# M3H5 register map
File version: 0.1
Registers are 32-bit, read-write, reset 0x0 unless marked. A register's access mark holds for its fields unless they carry their own. Offsets are from the block's base; [hi:lo] are bit positions; {n}, {i} and the like mark numbered series.

## PL
Base 0x400C0A00
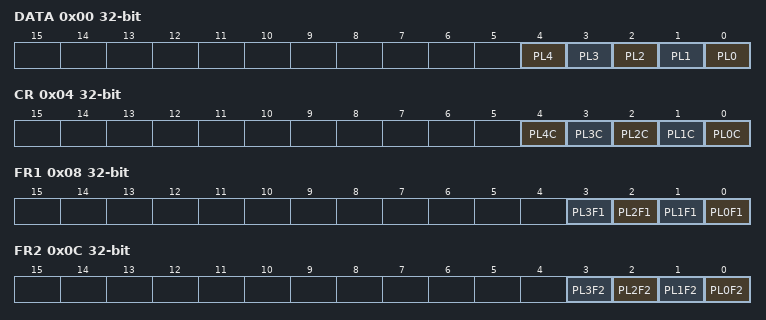
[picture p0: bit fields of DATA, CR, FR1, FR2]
0x00 DATA — PL Data Register
  [n] PL{n} (n=0..4)
0x04 CR — PL Control Register
  [n] PL{n}C (n=0..4)
0x08 FR1 — PL Function Register 1
  [n] PL{n}F1 (n=0..3)
0x0C FR2 — PL Function Register 2
  [n] PL{n}F2 (n=0..3)
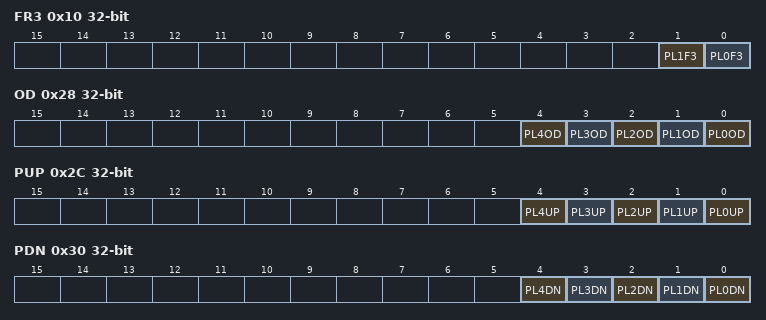
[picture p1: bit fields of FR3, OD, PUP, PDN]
0x10 FR3 — PL Function Register 3
  [1] PL1F3, [0] PL0F3
0x28 OD — PL Open Drain Control Register
  [n] PL{n}OD (n=0..4)
0x2C PUP — PL Pull-up Control Register
  [n] PL{n}UP (n=0..4)
0x30 PDN — PL Pull-Down Control Register
  [n] PL{n}DN (n=0..4)
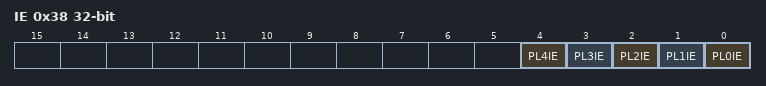
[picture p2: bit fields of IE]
0x38 IE — PL Input Enable Control Register
  [n] PL{n}IE (n=0..4)

## PM
Base 0x400C0B00
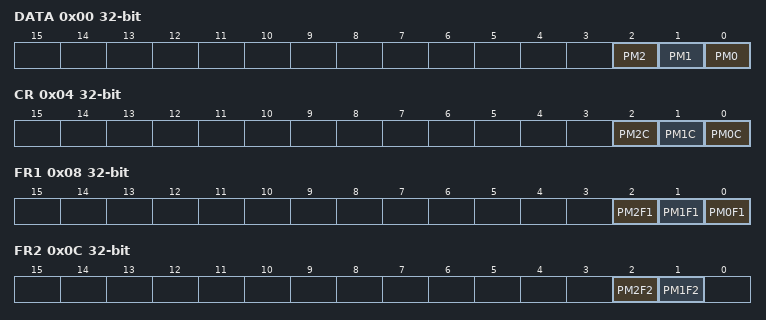
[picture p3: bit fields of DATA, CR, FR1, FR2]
0x00 DATA — PM Data Register
  [2] PM2, [1] PM1, [0] PM0
0x04 CR — PM Control Register
  [2] PM2C, [1] PM1C, [0] PM0C
0x08 FR1 — PM Function Register 1
  [2] PM2F1, [1] PM1F1, [0] PM0F1
0x0C FR2 — PM Function Register 2
  [2] PM2F2, [1] PM1F2
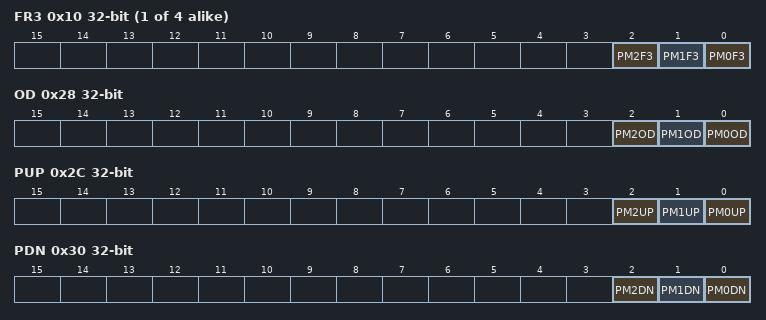
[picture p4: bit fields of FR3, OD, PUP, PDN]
{0x4+4i} FR{i} (i=3..6) — PM Function Register {i}
  [2] PM2F{i}, [1] PM1F{i}, [0] PM0F{i}
0x28 OD — PM Open Drain Control Register
  [2] PM2OD, [1] PM1OD, [0] PM0OD
0x2C PUP — PM Pull-up Control Register
  [2] PM2UP, [1] PM1UP, [0] PM0UP
0x30 PDN — PM Pull-Down Control Register
  [2] PM2DN, [1] PM1DN, [0] PM0DN
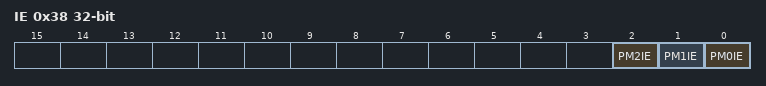
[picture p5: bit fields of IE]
0x38 IE — PM Input Enable Control Register
  [2] PM2IE, [1] PM1IE, [0] PM0IE

## PN
Base 0x400C0C00
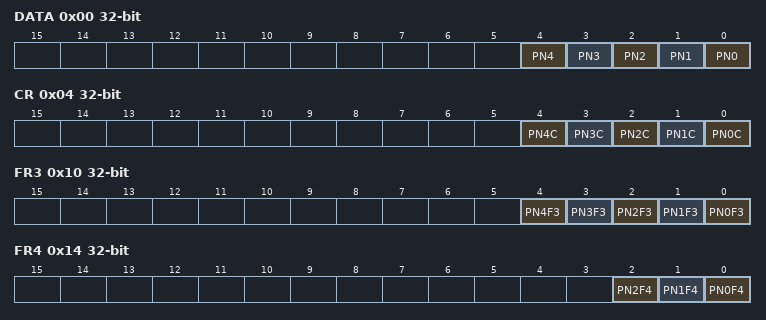
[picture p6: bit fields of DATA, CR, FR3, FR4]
0x00 DATA — PN Data Register
  [n] PN{n} (n=0..4)
0x04 CR — PN Control Register
  [n] PN{n}C (n=0..4)
0x10 FR3 — PN Function Register 3
  [n] PN{n}F3 (n=0..4)
0x14 FR4 — PN Function Register 4
  [2] PN2F4, [1] PN1F4, [0] PN0F4
0x18 FR5 — PN Function Register 5
  [3] PN3F5
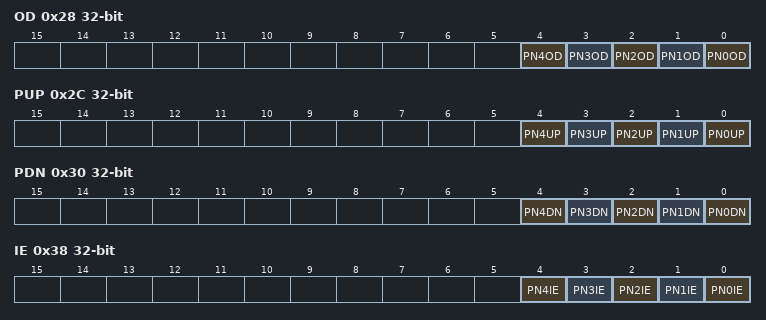
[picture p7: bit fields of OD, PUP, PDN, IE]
0x28 OD — PN Open Drain Control Register
  [n] PN{n}OD (n=0..4)
0x2C PUP — PN Pull-up Control Register
  [n] PN{n}UP (n=0..4)
0x30 PDN — PN Pull-Down Control Register
  [n] PN{n}DN (n=0..4)
0x38 IE — PN Input Enable Control Register
  [n] PN{n}IE (n=0..4)

## PP
Base 0x400C0D00
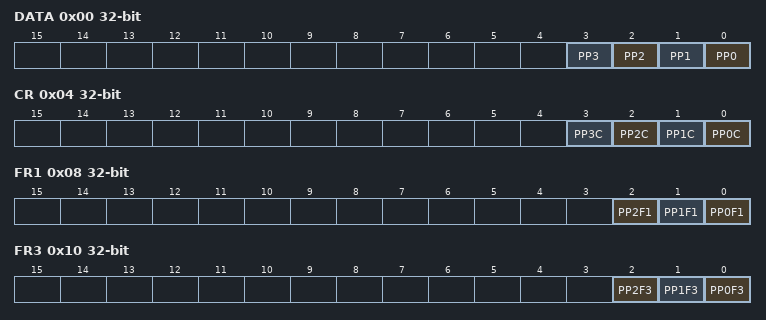
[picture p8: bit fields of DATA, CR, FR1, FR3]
0x00 DATA — PP Data Register
  [n] PP{n} (n=0..3)
0x04 CR — PP Control Register
  [n] PP{n}C (n=0..3)
0x08 FR1 — PP Function Register 1
  [2] PP2F1, [1] PP1F1, [0] PP0F1
0x10 FR3 — PP Function Register 3
  [2] PP2F3, [1] PP1F3, [0] PP0F3
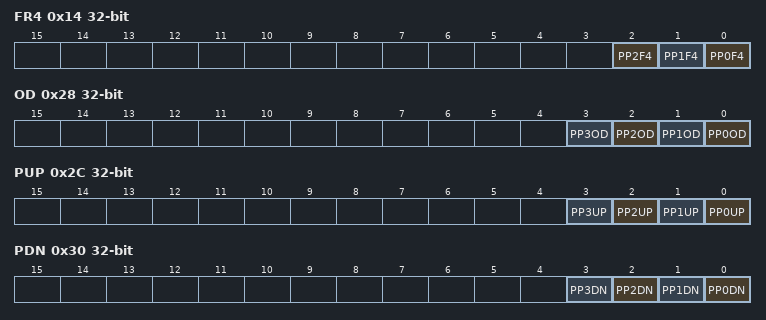
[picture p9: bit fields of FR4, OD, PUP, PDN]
0x14 FR4 — PP Function Register 4
  [2] PP2F4, [1] PP1F4, [0] PP0F4
0x28 OD — PP Open Drain Control Register
  [n] PP{n}OD (n=0..3)
0x2C PUP — PP Pull-up Control Register
  [n] PP{n}UP (n=0..3)
0x30 PDN — PP Pull-Down Control Register
  [n] PP{n}DN (n=0..3)
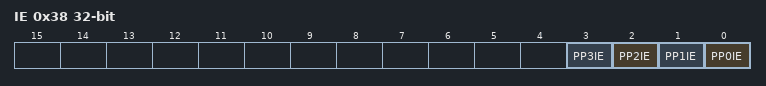
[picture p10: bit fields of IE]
0x38 IE — PP Input Enable Control Register
  [n] PP{n}IE (n=0..3)

## RTC
Base 0x400CC000
0x00 SECR 8-bit (reset mask 0x80) — RTC Sec setting register
  [6:0] SE
0x01 MINR 8-bit (reset mask 0x80) — RTC Min settging register
  [6:0] MI
0x02 HOURR 8-bit (reset mask 0xC0) — RTC Hour setting register
  [5:0] HO
0x04 DAYR 8-bit (reset mask 0xF8) — RTC Day setting register
  [2:0] WE
0x05 DATER 8-bit (reset mask 0xC0) — RTC Date setting register
  [5:0] DA
0x06 MONTHR_A 8-bit (reset mask 0xE0) — RTC Month settging register PAGE0
  [4:0] MO
0x06 MONTHR_B 8-bit (reset mask 0xFE) (RTC_MONTHR view) — RTC 24 hours _ 12 hours clock select register PAGE1
  [0] MO0
0x07 YEARR_A 8-bit reset not defined — RTC Year setting register PAGE0
  [7:0] YE
0x07 YEARR_B 8-bit (reset mask 0xFC) (RTC_YEARR view) — RTC Leap year register PAGE1
  [1:0] LEAP
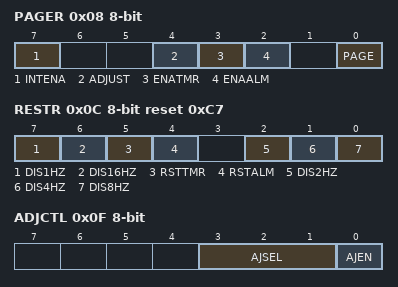
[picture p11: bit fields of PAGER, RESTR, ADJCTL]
0x08 PAGER 8-bit (reset mask 0xF3) — RTC Page register
  [7] INTENA, [4] ADJUST, [3] ENATMR, [2] ENAALM, [0] PAGE
0x0C RESTR 8-bit reset 0xC7 — RTC Reset register
  [7] DIS1HZ, [6] DIS16HZ, [5] RSTTMR, [4] RSTALM, [2] DIS2HZ, [1] DIS4HZ, [0] DIS8HZ
0x0E PROTECT 8-bit reset 0xC1 — RTC protect register
0x0F ADJCTL 8-bit (reset mask 0xF0) — RTC clock adjust control register
  [3:1] AJSEL, [0] AJEN
0x10 ADJDAT 8-bit reset not defined — RTC clock adjust data register

## RMC
Base 0x400E7000
0x00 EN — RMC Enable Register
  [0] RMCEN
0x04 REN — RMC Receive Enable Register
  [0] RMCREN
0x08 RBUF1 ro — RMC Receive Data Buffer Register 1
  [31:0] RMCRBUF
0x0C RBUF2 ro — RMC Receive Data Buffer Register 2
  [31:0] RMCRBUF
0x10 RBUF3 ro — RMC Receive Data Buffer Register 3
  [7:0] RMCRBUF
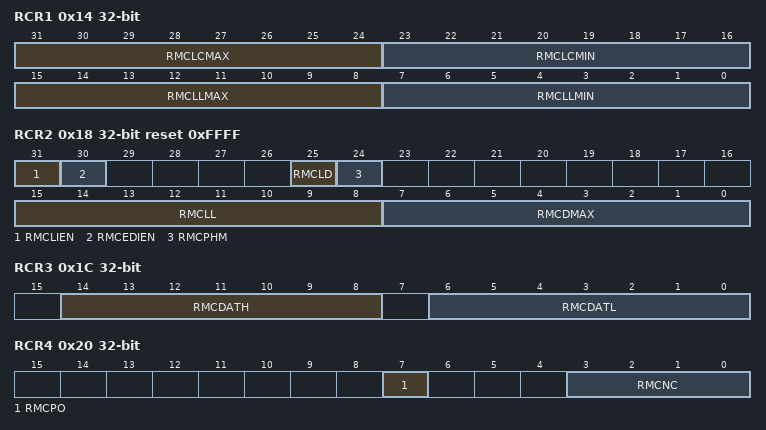
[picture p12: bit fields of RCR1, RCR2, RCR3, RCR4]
0x14 RCR1 — RMC Receive Control Register 1
  [31:24] RMCLCMAX, [23:16] RMCLCMIN, [15:8] RMCLLMAX, [7:0] RMCLLMIN
0x18 RCR2 reset 0xFFFF — RMC Receive Control Register 2
  [31] RMCLIEN, [30] RMCEDIEN, [25] RMCLD, [24] RMCPHM, [15:8] RMCLL, [7:0] RMCDMAX
0x1C RCR3 — RMC Receive Control Register 3
  [14:8] RMCDATH, [6:0] RMCDATL
0x20 RCR4 — RMC Receive Control Register 4
  [7] RMCPO, [3:0] RMCNC
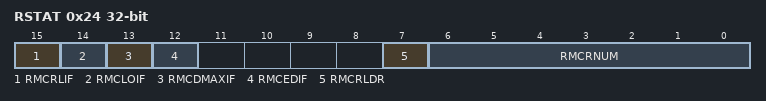
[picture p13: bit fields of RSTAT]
0x24 RSTAT ro — RMC Receive Status Register
  [15] RMCRLIF, [14] RMCLOIF, [13] RMCDMAXIF, [12] RMCEDIF, [7] RMCRLDR, [6:0] RMCRNUM
{0x24+4i} END{i} (i=1..3) — RMC Receive End Bit Number Register {i}
  [6:0] RMCEND{i}
0x34 FSSEL — RMC Frequency Selection Register
  [0] RMCCLK
